# M251_v1 register map
File version: 1.0
Registers are 32-bit, read-write, reset 0x0 unless marked. A register's access mark holds for its fields unless they carry their own. Offsets are from the block's base; [hi:lo] are bit positions; {n}, {i} and the like mark numbered series.

## WWDT — WWDT Register Map
Base 0x40040100
0x00 WWDT_RLDCNT wo — WWDT Reload Counter Register
  [31:0] RLDCNT — WWDT Reload Counter Register. Writing 0x00005AA5 to this register will reload the WWDT counter value to 0x3F. Note: User can only write WWDT_RLDCNT register to reload WWDT counter value when current WWDT counter value between 0 and CMPDAT (WWDT_CTL[21:16]). If user writes WWDT_RLDCNT when current WWDT counter value is larger than CMPDAT, WWDT reset signal will be generated immediately.
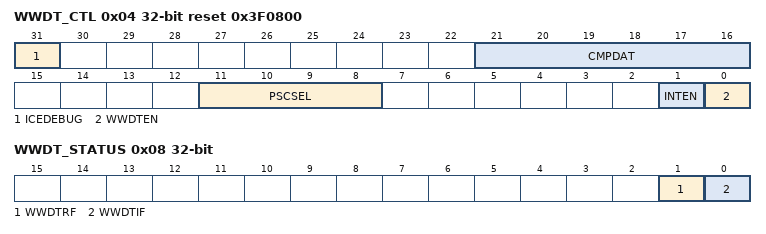
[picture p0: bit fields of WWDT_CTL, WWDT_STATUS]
0x04 WWDT_CTL reset 0x3F0800 — WWDT Control Register
  [31] ICEDEBUG — ICE Debug Mode Acknowledge Disable Bit. Note: WWDT down counter will keep going no matter CPU is held by ICE or not.
    0=ICE debug mode acknowledgement effects WWDT counting; 1=ICE debug mode acknowledgement Disabled
  [21:16] CMPDAT — WWDT Window Compare Register. Set this register to adjust the valid reload window. Note: User can only write WWDT_RLDCNT register to reload WWDT counter value when current WWDT counter value between 0 and CMPDAT. If user writes WWDT_RLDCNT register when current WWDT counter value larger than CMPDAT, WWDT reset signal will generate immediately.
  [11:8] PSCSEL — WWDT Counter Prescale Period Selection
    0=Pre-scale is 1; Max time-out period is 1 * 64 * WWDT_CLK; 1=Pre-scale is 2; Max time-out period is 2 * 64 * WWDT_CLK; 2=Pre-scale is 4; Max time-out period is 4 * 64 * WWDT_CLK; 3=Pre-scale is 8; Max time-out period is 8 * 64 * WWDT_CLK; 4=Pre-scale is 16; Max time-out period is 16 * 64 * WWDT_CLK; 5=Pre-scale is 32; Max time-out period is 32 * 64 * WWDT_CLK; 6=Pre-scale is 64; Max time-out period is 64 * 64 * WWDT_CLK; 7=Pre-scale is 128; Max time-out period is 128 * 64 * WWDT_CLK; 8=Pre-scale is 192; Max time-out period is 192 * 64 * WWDT_CLK; 9=Pre-scale is 256; Max time-out period is 256 * 64 * WWDT_CLK; 10=Pre-scale is 384; Max time-out period is 384 * 64 * WWDT_CLK; 11=Pre-scale is 512; Max time-out period is 512 * 64 * WWDT_CLK; 12=Pre-scale is 768; Max time-out period is 768 * 64 * WWDT_CLK; 13=Pre-scale is 1024; Max time-out period is 1024 * 64 * WWDT_CLK; 14=Pre-scale is 1536; Max time-out period is 1536 * 64 * WWDT_CLK; 15=Pre-scale is 2048; Max time-out period is 2048 * 64 * WWDT_CLK
  [1] INTEN — WWDT Interrupt Enable Bit. If this bit is enabled, the WWDT counter compare match interrupt signal is generated and inform to CPU.
    0=WWDT counter compare match interrupt Disabled; 1=WWDT counter compare match interrupt Enabled
  [0] WWDTEN — WWDT Enable Bit
    0=WWDT counter is stopped; 1=WWDT counter starts counting
0x08 WWDT_STATUS
  [1] WWDTRF — WWDT Timer-out Reset Flag. This bit indicates the system has been reset by WWDT time-out reset or not. Note: This bit is cleared by writing 1 to it.
    0=WWDT time-out reset did not occur; 1=WWDT time-out reset occurred
  [0] WWDTIF — WWDT Compare Match Interrupt Flag. This bit indicates the interrupt flag status of WWDT while WWDT counter value matches CMPDAT (WWDT_CTL[21:16]). Note: This bit is cleared by writing 1 to it.
    0=No effect; 1=WWDT counter value matches CMPDAT
0x0C WWDT_CNT ro reset 0x3F — WWDT Counter Value Register
  [5:0] CNTDAT — WWDT Counter Value. CNTDAT will be updated continuously to monitor 6-bit WWDT down counter value.

## EBI — EBI Register Map
Base 0x40010000
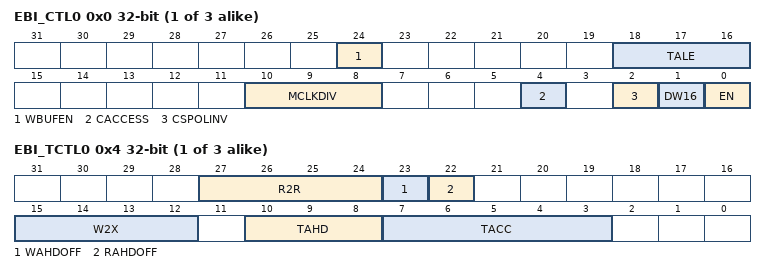
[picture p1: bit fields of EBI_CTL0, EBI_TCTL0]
{0x0+0x10*i} EBI_CTL{i} (i=0..2) — External Bus Interface Bank{i} Control Register
  [24] WBUFEN — EBI Write Buffer Enable Bit. Note: This bit only available in EBI_CTL0 register
    0=EBI write buffer Disabled; 1=EBI write buffer Enabled
  [18:16] TALE — Extend Time of ALE. The EBI_ALE high pulse period (tALE) to latch the address can be controlled by TALE. Note: This field only available in EBI_CTL0 register
  [10:8] MCLKDIV — External Output Clock Divider. The frequency of EBI output clock (MCLK) is controlled by MCLKDIV as follow:
    0=HCLK/1; 1=HCLK/2; 2=HCLK/4; 3=HCLK/8; 4=HCLK/16; 5=HCLK/32; 6=HCLK/64; 7=HCLK/128
  [4] CACCESS — Continuous Data Access Mode. When con tenuous access mode enabled, the tASU, tALE and tLHD cycles are bypass for continuous data transfer request.
    0=Continuous data access mode Disabled; 1=Continuous data access mode Enabled
  [2] CSPOLINV — Chip Select Pin Polar Inverse. This bit defines the active level of EBI chip select pin (EBI_nCS).
    0=Chip select pin (EBI_nCS) is active low; 1=Chip select pin (EBI_nCS) is active high
  [1] DW16 — EBI Data Width 16-bit Select. This bit defines if the EBI data width is 8-bit or 16-bit.
    0=EBI data width is 8-bit; 1=EBI data width is 16-bit
  [0] EN — EBI Enable Bit. This bit is the functional enable bit for EBI.
    0=EBI function Disabled; 1=EBI function Enabled
{0x4+0x10*i} EBI_TCTL{i} (i=0..2) — External Bus Interface Bank{i} Timing Control Register
  [27:24] R2R — Idle Cycle Between Read-to-read. This field defines the number of R2R idle cycle. When read action is finished and the next action is going to read, R2R idle cycle is inserted and EBI_nCS return to idle state.
  [23] WAHDOFF — Access Hold Time Disable Control When Write
    0=Data Access Hold Time (tAHD) during EBI writing Enabled; 1=Data Access Hold Time (tAHD) during EBI writing Disabled
  [22] RAHDOFF — Access Hold Time Disable Control When Read
    0=Data Access Hold Time (tAHD) during EBI reading Enabled; 1=Data Access Hold Time (tAHD) during EBI reading Disabled
  [15:12] W2X — Idle Cycle After Write. This field defines the number of W2X idle cycle. When write action is finished, W2X idle cycle is inserted and EBI_nCS return to idle state.
  [10:8] TAHD — EBI Data Access Hold Time. TAHD defines data access hold time (tAHD).
  [7:3] TACC — EBI Data Access Time. TACC defines data access time (tACC).
